# a34m41x register map
Vendor: ABOV Semiconductor Co., Ltd.; File version: 1.0
CPU: CM4 r0p1, little endian, MPU, FPU, VTOR, 4 interrupt priority bits
Registers are 32-bit, read-write, reset 0x0 unless marked. A register's access mark holds for its fields unless they carry their own. Offsets are from the block's base; [hi:lo] are bit positions; {n}, {i} and the like mark numbered series; 'fields as' and 'values as' point back to an identical list.

## PGA0 — Programmable Gain Amplifier
Base 0x4000B300
Same registers: PGA1 0x4000B304, PGA2 0x4000B308
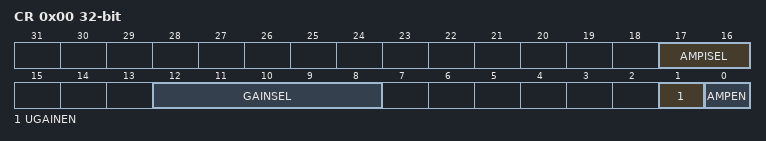
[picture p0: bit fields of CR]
0x00 CR — PGA Control Register
  [17:16] AMPISEL — OPAMP Current Setting Bit
    0=POSITIVE_0P (Current 0%); 1=POSITIVE_17P (Current 17%); 2=NEGATIVE_21P (Current -21%); 3=NEGATIVE_12P (Current -12%)
  [12:8] GAINSEL — OPAMP n GAIN Control Bit
    0=1_200 (GAIN 1.200); 1=1_304 (GAIN 1.304); 2=1_404 (GAIN 1.404); 3=1_500 (GAIN 1.500); 4=1_600 (GAIN 1.600); 5=1_702 (GAIN 1.702); 6=1_805 (GAIN 1.805); 7=1_905 (GAIN 1.905); 8=2_000 (GAIN 2.000); 9=2_182 (GAIN 2.182); 10=2_330 (GAIN 2.330); 11=2_500 (GAIN 2.500); 12=2_667 (GAIN 2.667); 13=2_927 (GAIN 2.927); 14=3_000 (GAIN 3.000); 15=3_158 (GAIN 3.158); 16=3_478 (GAIN 3.478); 17=3_871 (GAIN 3.871); 18=4_000 (GAIN 4.000); 19=4_364 (GAIN 4.364); 20=5_000 (GAIN 5.000); 21=5_854 (GAIN 5.854); 22=6_000 (GAIN 6.000); 23=6_857 (GAIN 6.857); 24=8_000 (GAIN 8.000); 25=8_571 (GAIN 8.571); 26=GAIN 10.00; 27=12_00 (GAIN 12.00); 28=15_00 (GAIN 15.00); 29=16_00 (GAIN 16.00)
  [1] UGAINEN — Unit Gain Enable Bit
    0=Disable; 1=Enable
  [0] AMPEN — PGA Enable Bit
    0=Disable; 1=Enable

## COMP0 — Comparator
Base 0x4000B380
Same registers: COMP1 0x4000B38C, COMP2 0x4000B398, COMP3 0x4000B3A4
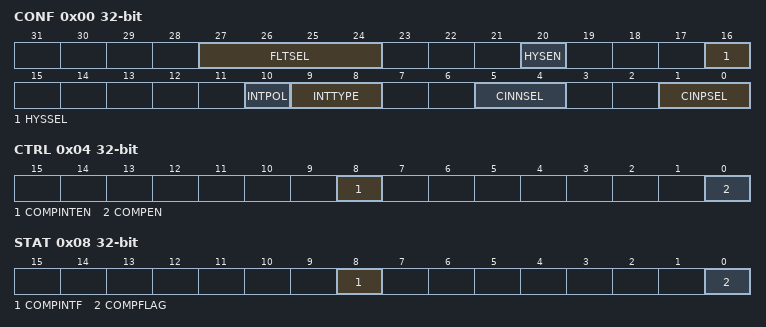
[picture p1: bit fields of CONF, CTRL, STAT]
0x00 CONF — Comparator 0 Configuration Register
  [27:24] FLTSEL — Filter Counter Bit Selection
  [20] HYSEN — Comparator Hysteresis Enable Bit
    0=Disable; 1=Enable
  [16] HYSSEL — Comparator Hysteresis Selection Bit
    0=5mV (5mV Hysteresis); 1=20mV Hysteresis
  [10] INTPOL — Interrupt Polarity Selection Bit
    0=Low; 1=High
  [9:8] INTTYPE — Interrupt Type Selection Bit
    0=Disable; 1=Level; 2=Single_Edge; 3=Both_Edge
  [5:4] CINNSEL — Comparator Reference (Input) Selection Bit
    0=Reference0 (Comparator Reference 0); 1=Reference1 (Comparator Reference 1)
  [1:0] CINPSEL — Comparator Input (Input) Selection Bit
    {v}=Input{v} (Comparator Input {v}) (v=0..3)
0x04 CTRL — Comparator 0 Control Register
  [8] COMPINTEN — Comparator Interrupt Enable Bit
    0=Disable; 1=Enable
  [0] COMPEN — Comparator Enable Bit
    0=Disable; 1=Enable
0x08 STAT — Comparator 0 Status Register
  [8] COMPINTF — Comparator Interrupt Flag Bit
  [0] COMPFLAG ro — Comparator Output Flag

## AES128 — Advanced Encryption Standard 128
Base 0x40000500
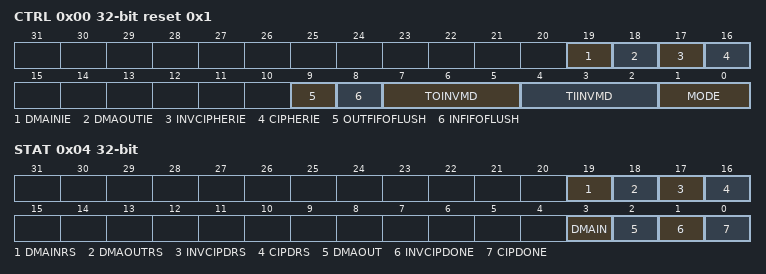
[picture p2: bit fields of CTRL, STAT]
0x00 CTRL reset 0x1 — AES Control Register
  [19] DMAINIE — AES DMA Input Complete Interrupt Enable
    0=Disable; 1=Enable
  [18] DMAOUTIE — AES DMA Output Complete Interrupt Enable
    0=Disable; 1=Enable
  [17] INVCIPHERIE — AES Inverse Cipher Mode Complete Interrupt Enable
    0=Disable; 1=Enable
  [16] CIPHERIE — AES Cipher Mode Complete Interrupt Enable
    0=Disable; 1=Enable
  [9] OUTFIFOFLUSH — AES Output FIFO Erase Bit(Auto Clear)
    0=Disable; 1=Enable
  [8] INFIFOFLUSH — AES Input FIFO Erase Bit(Auto Clear)
    0=Disable; 1=Enable
  [7:5] TOINVMD — AES TEXT OUT Arrange Mode Setting Bit
    0=Default WORD Row(LSB); 1=WORD_INV (WORD Inverse Mode(MSB)); 2=BYTE_INV_INWORD (BYTE Inverse in WORD Mode(MSB)); 4=BYTE_INV (BYTE Inverse Mode(MSB))
  [4:2] TIINVMD — AES TEXT IN Arrange Mode Setting Bit
    values as TOINVMD
  [1:0] MODE — AES Mode Selection Bit
    1=Cipher Mode; 2=Inverse Cipher Mode
0x04 STAT (reset mask 0xFFFF) — AES Status Register
  [19] DMAINRS ro — AES DMA Input Complete Status Bit(Raw data)
  [18] DMAOUTRS ro — AES DMA Output Complete Status Bit(Raw data)
  [17] INVCIPDRS ro — AES DMA Input Complete Status Bit(Raw data)
  [16] CIPDRS ro — AES DMA Input Complete Status Bit(Raw data)
  [3] DMAIN — AES DMA Input Complete Flag Bit
    0=Not_Complete; 1=Done_Clear (Inverse Ciper Done (to clear write '1'))
  [2] DMAOUT — AES DMA Output Complete Flag Bit
    values as DMAIN
  [1] INVCIPDONE — AES Inverse Cipher Done Flag Bit
    values as DMAIN
  [0] CIPDONE — AES Cipher Done Flag Bit
    0=Not_Complete; 1=Done_Clear (Ciper Done (to clear write '1'))
0x08 INFIFO wo — AES Input FIFO Register
  [31:0] TEXTIN — TEST IN FIFO Register
0x0C OUTFIFO ro — AES Output FIFO Register
  [31:0] TEXTOUT — TEST OUT FIFO Register
{0x10+4i} KEYIN{i} (i=0..3) — AES KEY IN Register {i}
  [31:0] KEYIND{i} — KEY IN Value Register {i}
{0x20+4i} TEXTIN{i} ro (i=0..3) — AES TEXT IN {i} Register
  [31:0] TEXTIN{i} — TEST IN Value Register
{0x30+4i} TEXTOUT{i} ro (i=0..3) — AES TEXT OUT Register {i}
  [31:0] OUTD{i} — TEXT OUT Value Bit

## RNG — Random Number Generator
Base 0x40000A00
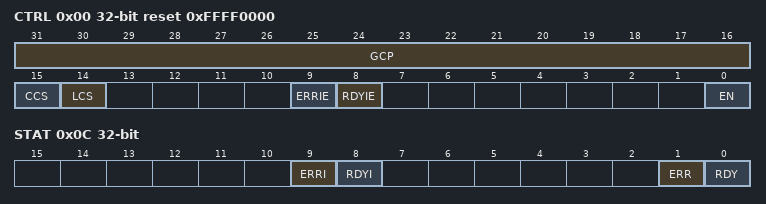
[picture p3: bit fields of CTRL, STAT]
0x00 CTRL reset 0xFFFF0000 — RNG Control Register
  [31:16] GCP — Generation Counter Parameter
  [15] CCS — CASR Clock Selection Bit
    0=LSI; 1=HSI
  [14] LCS — LFSR Clock Selection Bit
    0=LSI; 1=HSI
  [9] ERRIE — Error Interrupt Enable Bit
    0=Disable; 1=Enable
  [8] RDYIE — RNGD Data Ready Interrupt Enable Bit
    0=Disable; 1=Enable
  [0] EN — RNG Start Bit
    0=STOP (RNG STOP); 1=START (RNG START)
0x04 SEED — RNG SEED Register
  [31:0] SEED — RND Seed Setting Bit
0x08 RNGD ro — RNG Random number data register
  [31:0] RNG_Data — Random number generation data bit
0x0C STAT — RNG Status Register
  [9] ERRI — Error Interrupt Flag Bit
  [8] RDYI — RNGD Data Ready Interrupt Flag Bit
  [1] ERR — Error Status Bit
  [0] RDY — RNGD Data Ready Status Bit

## CRC — CYCLIC REDUNDANCY CHECK AND CHECKSUM
Base 0x41002000
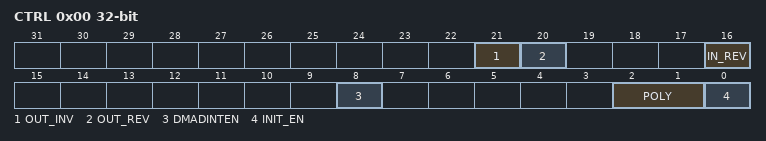
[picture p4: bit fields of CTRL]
0x00 CTRL — CRC Control Register
  [21] OUT_INV — CRC Output Data Inversion Enable bit
  [20] OUT_REV — CRC Output Data Reverse Enable Bit
  [16] IN_REV — Input Data Reverse Mode Selection Bit
  [8] DMADINTEN — DMA Done Interrupt Enable Bit
  [2:1] POLY — Polynomal Selection Bit
    0=CRC32 (0x04C1_1DB7); 1=CRC16 (0x8005); 2=CRC8 (0x07); 3=CRC7 (0x09)
  [0] INIT_EN wo — CRC Init Register Apply Bit
0x04 INIT — CRC Init value Register
  [31:0] INIT — CRC Initial Value
0x08 IDR wo — CRC Input Data Register
  [31:0] IDR — CRC Input Data Bit
0x08 ODR ro reset 0xFFFFFFFF — CRC Output Data Register
  [31:0] ODR — CRC Output Data Bit
0x0C STAT — CRC Status Register
  [8] DMADINT — DMA Done Interrupt Flag Bit
